AUTOSAR XML (schema 4-3-0)
standard types defined: boolean, float32, sint16, sint32, sint8, uint16, uint32, uint64, uint8
package /Clusters
  ethernet cluster EthernetCluster1: baudrate=100000, protocol-name=ETHERNET
    ethernet physical channel RdrNet: comm-connectors=[cnctr_ADAS_RdrNet, cnctr_RDR_RdrNet, cnctr_External_Tool]
      pdu triggering PDUTriggering1: pdu=GenerelPurposePDU1, from ADAS
      pdu triggering PDUTriggering2: pdu=GenerelPurposePDU2, to ADAS
      pdu triggering PDUTriggering3: pdu=GenerelPurposePDU3, from RDR
      pdu triggering PDUTriggering4: pdu=GenerelPurposePDU4, to RDR
      pdu triggering PDUTriggering7: pdu=GenerelPurposePDU7, to RDR
      pdu triggering PDUTriggering9: pdu=GenerelPurposePDU9, to ADAS
      pdu triggering PDUTriggering12_Vehicle_Status_ADAS_to_RDR1: pdu=signalPdu_ADAS_Vehicle_Status, from ADAS, to RDR
      pdu triggering PDUTriggering14_Detections_RDR1_to_ADAS: pdu=signalPdu_RDR_1_Detections, from RDR, to ADAS
      pdu triggering PDUTriggering15_SW_Info_RDR1_to_ADAS: pdu=signalPdu_RDR_1_SW_Info, from RDR, to ADAS
      pdu triggering PDUTriggering16_RDR_Status_RDR1_to_ADAS: pdu=signalPdu_RDR_1_Status, from RDR, to ADAS
      pdu triggering PDUTriggering14_Detections_RDR1_to_ADAS_Transport: pdu=signalPdu_RDR_1_Detections_Transport, from RDR, to ADAS
      10 x network endpoint:
        NEP_ANY_IP: network-endpoint-addresses=ipv-4-configuration={ipv-4-address=ANY, ipv-4-address-source=FIXED}
        NEP_ADAS_RdrNet_CtrlRxMulticast: network-endpoint-addresses=ipv-4-configuration={ipv-4-address=239.192.255.251, ipv-4-address-source=FIXED}
        NEP_ADAS_RdrNet_Unicast: network-endpoint-addresses=ipv-4-configuration={ipv-4-address=192.168.1.100, ipv-4-address-source=FIXED, network-mask=255.255.255.0}
        NEP_SRR_1_RdrNet_Unicast: network-endpoint-addresses=ipv-4-configuration={ipv-4-address=192.168.1.71, ipv-4-address-source=FIXED, network-mask=255.255.255.0}
        NEP_RdrNet_ExternalTool: network-endpoint-addresses=ipv-4-configuration={ipv-4-address=192.168.1.40, ipv-4-address-source=FIXED, network-mask=255.255.255.0}
        SD_AnyNEP_ADAS_1
        SD_AnyNEP_RDR_1
        SD_AnyNEP_RDR_SRR_2_1
        SD_AnyNEP_RDR_2
        SD_AnyNEP_ADAS_2
      so-ad-config:
        6 x socket connection bundle:
          ConnectionBundle_ADAS: socket-connection{client-port=SocAddr_RDR_1_RdrNet_UDP_30501_client, pdus=socket-connection-ipdu-identifier={header-id=16809985, pdu-triggering=PDUTriggering12_Vehicle_Status_ADAS_to_RDR1, routing-group=SoAdRoutingGroup1}}, server-port=SocAddr_ADAS_RdrNet_UDP_34501_server
          ConnectionBundle_RDR_1: socket-connection{client-port=SocAddr_ADAS_RdrNet_UDP_30501_client, pdus=[{header-id=1081345, pdu-triggering=PDUTriggering14_Detections_RDR1_to_ADAS_Transport, routing-group=SoAdRoutingGroup2}, {header-id=1212418, pdu-triggering=PDUTriggering15_SW_Info_RDR1_to_ADAS, routing-group=SoAdRoutingGroup3}, {header-id=1146883, pdu-triggering=PDUTriggering16_RDR_Status_RDR1_to_ADAS, routing-group=SoAdRoutingGroup4}]}, server-port=SocAddr_RDR_1_RdrNet_UDP_34501_server
          ConnectionBundle1: socket-connection{client-port=SD_SocketAddress_Client1, pdus=[{header-id=4294934784, pdu-triggering=PDUTriggering1}, {header-id=4294934784, pdu-triggering=PDUTriggering2}]}, server-port=SD_SocketAddress_ADAS1
          ConnectionBundle2: socket-connection{client-port=SD_SocketAddress_Client2, pdus=[{header-id=4294934784, pdu-triggering=PDUTriggering3}, {header-id=4294934784, pdu-triggering=PDUTriggering4}]}, server-port=SD_SocketAddress_RDR1
          ConnectionBundle4: socket-connection{client-port=SD_SocketAddress_Client4, pdus=socket-connection-ipdu-identifier={header-id=4294934784, pdu-triggering=PDUTriggering7}}, server-port=SD_SocketAddress_RDR2
          ConnectionBundle6: socket-connection{client-port=SD_SocketAddress_Client6, pdus=socket-connection-ipdu-identifier={header-id=4294934784, pdu-triggering=PDUTriggering9}}, server-port=SD_SocketAddress_ADAS2
        15 x socket address:
          SocAddr_ADAS_RdrNet_UDP_30501_client: connector=cnctr_ADAS_RdrNet
            application endpoint AEP_AEP_ADAS_RdrNet_UDP_30501_UDP30501_client: network-endpoint=NEP_ADAS_RdrNet_Unicast, tp-configuration=udp-tp=udp-tp-port={dynamically-assigned=false, port-number=30501}
              consumed service instance consService_ADAS_Detections_from_RDR_1: provided-service-instance=provService_RDR_1_Detections, sd-client-config={client-service-major-version=1, client-service-minor-version=0, initial-find-behavior={initial-delay-max-value=0.01, initial-delay-min-value=0.01, initial-repetitions-base-delay=0.03, initial-repetitions-max=3}, request-response-delay={max-value=0.01, min-value=0.01}, ttl=3}
                consumed event group consServiceGrp_ADAS_Detections_from_RDR_1: event-group-identifier=0x1, instance-identifier=1, routing-group=SoAdRoutingGroup2, sd-client-config={client-service-major-version=1, client-service-minor-version=0, initial-find-behavior={initial-delay-max-value=0.01, initial-delay-min-value=0.01, initial-repetitions-base-delay=0.03, initial-repetitions-max=3}, request-response-delay={max-value=0.01, min-value=0.01}, ttl=3}
              consumed service instance consService_ADAS_SW_Info_from_RDR_1: provided-service-instance=provService_RDR_1_SW_Info, sd-client-config={client-service-major-version=1, client-service-minor-version=0, initial-find-behavior={initial-delay-max-value=0.01, initial-delay-min-value=0.01, initial-repetitions-base-delay=0.03, initial-repetitions-max=3}, request-response-delay={max-value=0.01, min-value=0.01}, ttl=3}
                consumed event group consServiceGrp_ADAS_SW_Info_from_RDR_1: event-group-identifier=0x1, instance-identifier=1, routing-group=SoAdRoutingGroup3, sd-client-config={client-service-major-version=1, client-service-minor-version=0, initial-find-behavior={initial-delay-max-value=0.01, initial-delay-min-value=0.01, initial-repetitions-base-delay=0.03, initial-repetitions-max=3}, request-response-delay={max-value=0.01, min-value=0.01}, ttl=3}
              consumed service instance consService_ADAS_Status_from_RDR_1: provided-service-instance=provService_RDR_1_Status, sd-client-config={client-service-major-version=1, client-service-minor-version=0, initial-find-behavior={initial-delay-max-value=0.01, initial-delay-min-value=0.01, initial-repetitions-base-delay=0.03, initial-repetitions-max=3}, request-response-delay={max-value=0.01, min-value=0.01}, ttl=3}
                consumed event group consServiceGrp_ADAS_Status_from_RDR_1: event-group-identifier=0x1, instance-identifier=1, routing-group=SoAdRoutingGroup4, sd-client-config={client-service-major-version=1, client-service-minor-version=0, initial-find-behavior={initial-delay-max-value=0.01, initial-delay-min-value=0.01, initial-repetitions-base-delay=0.03, initial-repetitions-max=3}, request-response-delay={max-value=0.01, min-value=0.01}, ttl=3}
          SocAddr_ADAS_RdrNet_UDP_34501_server: connector=cnctr_ADAS_RdrNet
            application endpoint AEP_AEP_ADAS_RdrNet_UDP_34501_UDP34501_server: network-endpoint=NEP_ADAS_RdrNet_Unicast, tp-configuration=udp-tp=udp-tp-port={dynamically-assigned=false, port-number=34501}
              provided service instance provService_ADAS_Vehicle_Status: instance-identifier=1, sd-server-config={initial-offer-behavior={initial-delay-max-value=0.01, initial-delay-min-value=0.01, initial-repetitions-base-delay=0.03, initial-repetitions-max=3}, offer-cyclic-delay=1, request-response-delay={max-value=0.01, min-value=0.01}, server-service-major-version=1, server-service-minor-version=0, ttl=3}, service-identifier=256
                event handler EventGroup_ADAS:
                  consumed-event-group=consServiceGrp_RDR_1_ADAS_Vehicle_Status
                  routing-group=SoAdRoutingGroup1
                  sd-server-config={initial-offer-behavior={initial-delay-max-value=0.01, initial-delay-min-value=0.01, initial-repetitions-base-delay=0.03, initial-repetitions-max=3}, offer-cyclic-delay=1, request-response-delay={max-value=0.01, min-value=0.01}, server-service-major-version=1, server-service-minor-version=0, ttl=3}
          SocAddr_RDR_1_RdrNet_UDP_30501_client: connector=cnctr_RDR_RdrNet
            application endpoint AEP_AEP_RDR_1_RdrNet_UDP_30501_client: network-endpoint=NEP_SRR_1_RdrNet_Unicast, tp-configuration=udp-tp=udp-tp-port={dynamically-assigned=false, port-number=30501}
              consumed service instance consService_RDR_1_ADAS_Vehicle_Status: provided-service-instance=provService_ADAS_Vehicle_Status, sd-client-config={client-service-major-version=1, client-service-minor-version=0, initial-find-behavior={initial-delay-max-value=0.01, initial-delay-min-value=0.01, initial-repetitions-base-delay=0.03, initial-repetitions-max=3}, request-response-delay={max-value=0.01, min-value=0.01}, ttl=3}
                consumed event group consServiceGrp_RDR_1_ADAS_Vehicle_Status: event-group-identifier=0x1, instance-identifier=1, routing-group=SoAdRoutingGroup1, sd-client-config={client-service-major-version=1, client-service-minor-version=0, initial-find-behavior={initial-delay-max-value=0.01, initial-delay-min-value=0.01, initial-repetitions-base-delay=0.03, initial-repetitions-max=3}, request-response-delay={max-value=0.01, min-value=0.01}, ttl=3}
          SocAddr_RDR_1_RdrNet_UDP_34501_server: connector=cnctr_RDR_RdrNet
            application endpoint AEP_AEP_RDR_1_RdrNet_UDP_34501_server: network-endpoint=NEP_SRR_1_RdrNet_Unicast, tp-configuration=udp-tp=udp-tp-port={dynamically-assigned=false, port-number=34501}
              provided service instance provService_RDR_1_Detections: instance-identifier=1, sd-server-config={initial-offer-behavior={initial-delay-max-value=0.01, initial-delay-min-value=0.01, initial-repetitions-base-delay=0.03, initial-repetitions-max=3}, offer-cyclic-delay=1, request-response-delay={max-value=0.01, min-value=0.01}, server-service-major-version=1, server-service-minor-version=0, ttl=3}, service-identifier=16
                event handler EventGroup_RDR_1:
                  consumed-event-group=consServiceGrp_ADAS_Detections_from_RDR_1
                  routing-group=SoAdRoutingGroup2
                  sd-server-config={initial-offer-behavior={initial-delay-max-value=0.01, initial-delay-min-value=0.01, initial-repetitions-base-delay=0.03, initial-repetitions-max=3}, offer-cyclic-delay=1, request-response-delay={max-value=0.01, min-value=0.01}, server-service-major-version=1, server-service-minor-version=0, ttl=3}
              provided service instance provService_RDR_1_SW_Info: instance-identifier=1, sd-server-config={initial-offer-behavior={initial-delay-max-value=0.01, initial-delay-min-value=0.01, initial-repetitions-base-delay=0.03, initial-repetitions-max=3}, offer-cyclic-delay=1, request-response-delay={max-value=0.01, min-value=0.01}, server-service-major-version=1, server-service-minor-version=0, ttl=3}, service-identifier=18
                event handler EventGroup_RDR_1:
                  consumed-event-group=consServiceGrp_ADAS_SW_Info_from_RDR_1
                  routing-group=SoAdRoutingGroup3
                  sd-server-config={initial-offer-behavior={initial-delay-max-value=0.01, initial-delay-min-value=0.01, initial-repetitions-base-delay=0.03, initial-repetitions-max=3}, offer-cyclic-delay=1, request-response-delay={max-value=0.01, min-value=0.01}, server-service-major-version=1, server-service-minor-version=0, ttl=3}
              provided service instance provService_RDR_1_Status: instance-identifier=1, sd-server-config={initial-offer-behavior={initial-delay-max-value=0.01, initial-delay-min-value=0.01, initial-repetitions-base-delay=0.03, initial-repetitions-max=3}, offer-cyclic-delay=1, request-response-delay={max-value=0.01, min-value=0.01}, server-service-major-version=1, server-service-minor-version=0, ttl=3}, service-identifier=17
                event handler EventGroup_RDR_1:
                  consumed-event-group=consServiceGrp_ADAS_Status_from_RDR_1
                  routing-group=SoAdRoutingGroup4
                  sd-server-config={initial-offer-behavior={initial-delay-max-value=0.01, initial-delay-min-value=0.01, initial-repetitions-base-delay=0.03, initial-repetitions-max=3}, offer-cyclic-delay=1, request-response-delay={max-value=0.01, min-value=0.01}, server-service-major-version=1, server-service-minor-version=0, ttl=3}
          SocAddr_External_Tool: connector=cnctr_External_Tool
            application endpoint AEP_AEP_External_Tool: network-endpoint=NEP_RdrNet_ExternalTool, tp-configuration=udp-tp=udp-tp-port={dynamically-assigned=false, port-number=5555}
          SocAddr_Ctrl_ANY: multicast-connector=[cnctr_ADAS_RdrNet, cnctr_RDR_RdrNet]
            application endpoint AEP_SocAddr_Ctrl_ANY: network-endpoint=NEP_ANY_IP
          SocAddr_SD_Multicast: multicast-connector=[cnctr_ADAS_RdrNet, cnctr_RDR_RdrNet]
            application endpoint AEP_SocAddr_SD_Multicast: network-endpoint=NEP_ADAS_RdrNet_CtrlRxMulticast, tp-configuration=udp-tp=udp-tp-port=port-number=30490
          SD_SocketAddress_ADAS1: connector=cnctr_ADAS_RdrNet
            application endpoint SD_SocketAddress_ADAS1: network-endpoint=NEP_ADAS_RdrNet_Unicast, tp-configuration=udp-tp=udp-tp-port={dynamically-assigned=false, port-number=30490}
          SD_SocketAddress_Client1
            application endpoint SD_SocketAddress_Client1: network-endpoint=SD_AnyNEP_ADAS_1, tp-configuration=udp-tp=udp-tp-port=dynamically-assigned=true
          SD_SocketAddress_RDR1: connector=cnctr_RDR_RdrNet
            application endpoint SD_SocketAddress_RDR1: network-endpoint=NEP_SRR_1_RdrNet_Unicast, tp-configuration=udp-tp=udp-tp-port={dynamically-assigned=false, port-number=30490}
          SD_SocketAddress_Client2
            application endpoint SD_SocketAddress_Client2: network-endpoint=SD_AnyNEP_RDR_1, tp-configuration=udp-tp=udp-tp-port=dynamically-assigned=true
          SD_SocketAddress_RDR2: connector=cnctr_RDR_RdrNet
            application endpoint SD_SocketAddress_RDR2: network-endpoint=NEP_ADAS_RdrNet_CtrlRxMulticast, tp-configuration=udp-tp=udp-tp-port={dynamically-assigned=false, port-number=30490}
          SD_SocketAddress_Client4
            application endpoint SD_SocketAddress_Client4: network-endpoint=SD_AnyNEP_RDR_2, tp-configuration=udp-tp=udp-tp-port=dynamically-assigned=true
          SD_SocketAddress_ADAS2: connector=cnctr_ADAS_RdrNet
            application endpoint SD_SocketAddress_ADAS2: network-endpoint=NEP_ADAS_RdrNet_CtrlRxMulticast, tp-configuration=udp-tp=udp-tp-port={dynamically-assigned=false, port-number=30490}
          SD_SocketAddress_Client6
            application endpoint SD_SocketAddress_Client6: network-endpoint=SD_AnyNEP_ADAS_2, tp-configuration=udp-tp=udp-tp-port=dynamically-assigned=true
package /PDUs/PDU_RdrNet
  pdu signalPdu_ADAS_Vehicle_Status: length=79, transmission-mode-true-timing=event-controlled-timing=number-of-repetitions=0, unused-bit-pattern=255
    signal iSignal_ADAS_Vehicle_Status: start 0, 568 bit, opaque, system signal sysSignal_ADAS_Vehicle_Status, data-transformations=SOMEIP_XFORMER_BE, data-type-policy=TRANSFORMING-I-SIGNAL, implementation-data-type=SR_VEHICLE_STATUS_RECORD, someip-transformation-i-signal-props{transformer=SOMEIP_XFORM_TECH_BE, message-type=NOTIFICATION, session-handling-sr=SESSION-HANDLING-ACTIVE}, transfer-property=TRIGGERED, to RDR
  pdu signalPdu_RDR_1_Detections: length=38632, transmission-mode-true-timing=event-controlled-timing=number-of-repetitions=0, unused-bit-pattern=255
    signal iSignal_RDR_1_Detections: start 0, 309056 bit, opaque, system signal sysSignal_RDR_1_Detections, data-transformations=SOMEIP_XFORMER_BE, data-type-policy=TRANSFORMING-I-SIGNAL, implementation-data-type=SR_DETECTIONS_RECORD, someip-transformation-i-signal-props{transformer=SOMEIP_XFORM_TECH_BE, message-type=NOTIFICATION, session-handling-sr=SESSION-HANDLING-ACTIVE}, transfer-property=TRIGGERED, to ADAS
  general purpose i pdu signalPdu_RDR_1_Detections_Transport: category=SOMEIP_SEGMENTED_IPDU, length=1404
  pdu signalPdu_RDR_1_SW_Info: length=90, transmission-mode-true-timing=event-controlled-timing=number-of-repetitions=0, unused-bit-pattern=255
    signal iSignal_RDR_1_SW_Info: start 0, 656 bit, opaque, system signal sysSignal_RDR_1_SW_Info, data-transformations=SOMEIP_XFORMER_BE, data-type-policy=TRANSFORMING-I-SIGNAL, implementation-data-type=SR_RADAR_SW_INFO_RECORD, someip-transformation-i-signal-props{transformer=SOMEIP_XFORM_TECH_BE, message-type=NOTIFICATION, session-handling-sr=SESSION-HANDLING-ACTIVE}, transfer-property=TRIGGERED, to ADAS
  pdu signalPdu_RDR_1_Status: length=269, transmission-mode-true-timing=event-controlled-timing=number-of-repetitions=0, unused-bit-pattern=255
    signal iSignal_RDR_1_Status: start 0, 2088 bit, opaque, system signal sysSignal_RDR_1_Status, data-transformations=SOMEIP_XFORMER_BE, data-type-policy=TRANSFORMING-I-SIGNAL, implementation-data-type=SR_RADAR_STATUS_RECORD, someip-transformation-i-signal-props{transformer=SOMEIP_XFORM_TECH_BE, message-type=NOTIFICATION, session-handling-sr=SESSION-HANDLING-ACTIVE}, transfer-property=TRIGGERED, to ADAS
package /PDUs/GeneralPurposePDUs
  general purpose pdu GenerelPurposePDU{1..9}: category=SD, length=0
package /Transformer
  data transformation set SOMEIP_XFORMER
    data transformation SOMEIP_XFORMER_BE: execute-despite-data-unavailability=false, transformer-chain=SOMEIP_XFORM_TECH_BE
    data transformation SOMEIP_XFORMER_LE: execute-despite-data-unavailability=false, transformer-chain=SOMEIP_XFORM_TECH_LE
    transformation technology SOMEIP_XFORM_TECH_BE: buffer-properties={buffer-computation=compu-rational-coeffs={compu-numerator=[8, 1], compu-denominator=1}, header-length=64, in-place=false}, protocol=SOMEIP, someip-transformation-description{alignment=8, byte-order=big-endian, interface-version=1}, transformer-class=SERIALIZER, version=1
    transformation technology SOMEIP_XFORM_TECH_LE: buffer-properties={buffer-computation=compu-rational-coeffs={compu-numerator=[8, 1], compu-denominator=1}, header-length=64, in-place=false}, protocol=SOMEIP, someip-transformation-description{alignment=8, byte-order=little-endian, interface-version=1}, transformer-class=SERIALIZER, version=1
package /System
  system System
    system mapping Mapping
      data-mappings:
        data-element=SWC_ADAS_Com.RootComposition.PP_Vehicle_Status.Vehicle_Status, system-signal=sysSignal_ADAS_Vehicle_Status
        data-element=SWC_RDR_1_Veh_Com.RootComposition.PP_DetectionList_Event.DetectionList_Event, system-signal=sysSignal_RDR_1_Detections
        data-element=SWC_ADAS_Com.RootComposition.RP_ADAS_RDR_1_DetectionList.DetectionList_Event, system-signal=sysSignal_RDR_1_Detections
        data-element=SWC_RDR_1_Veh_Com.RootComposition.PP_RDR_Radar_SW_Info.RDR_SW_Info, system-signal=sysSignal_RDR_1_SW_Info
        data-element=SWC_ADAS_Com.RootComposition.RP_ADAS_RDR_1_Radar_SW_Info.RDR_SW_Info, system-signal=sysSignal_RDR_1_SW_Info
        data-element=SWC_RDR_1_Veh_Com.RootComposition.PP_RDR_Radar_Status.RDR_Status, system-signal=sysSignal_RDR_1_Status
        data-element=SWC_ADAS_Com.RootComposition.RP_ADAS_RDR_1_Radar_Status.RDR_Status, system-signal=sysSignal_RDR_1_Status
        data-element=SWC_RDR_1_Veh_Com.RootComposition.RP_Vehicle_Status.Vehicle_Status, system-signal=sysSignal_ADAS_Vehicle_Status
      sw-mappings:
        swc to ecu mapping ECUMapping1: component=RootComposition.SWC_ADAS_Com, ecu-instance=ADAS
        swc to ecu mapping ECUMapping2: component=RootComposition.SWC_RDR_1_Veh_Com, ecu-instance=RDR
    root-software-compositions:
      root sw composition prototype RootComposition: software-composition=ECU_Composition
package /ECUs
  ecu instance ADAS
    ethernet communication controller ADAS_Eth_Controller_1: mac-unicast-address=00:1A:A0:22:0E:A9
      coupling port ADAS_CouplingPort1: connection-negotiation-behavior=MASTER
    ethernet communication connector cnctr_ADAS_RdrNet: comm-controller=ADAS_Eth_Controller_1, pnc-gateway-type=NONE, maximum-transmission-unit=1500
  ecu instance External_Tool
    ethernet communication controller External_Tool_EthConnector1_Controller: mac-unicast-address=00:1B:B0:22:0C:A0
      coupling port Ext_Tool_CouplingPort1: connection-negotiation-behavior=SLAVE
    ethernet communication controller cnctr_External_Tool_Controller: mac-unicast-address=00:1B:B0:22:0C:A0
      coupling port Ext_Tool_CouplingPort1: connection-negotiation-behavior=SLAVE
    ethernet communication connector External_Tool_EthConnector1: comm-controller=External_Tool_EthConnector1_Controller, pnc-gateway-type=NONE
    ethernet communication connector cnctr_External_Tool: comm-controller=cnctr_External_Tool_Controller, pnc-gateway-type=NONE
  ecu instance RDR
    ethernet communication controller RDR_1_Eth_Controller_1: mac-unicast-address=00:1A:A0:22:0E:B0
      coupling port RDR_CouplingPort1: connection-negotiation-behavior=SLAVE
    ethernet communication connector cnctr_RDR_RdrNet: comm-controller=RDR_1_Eth_Controller_1, pnc-gateway-type=NONE, maximum-transmission-unit=1500
package /Interfaces/Events
  4 x sender receiver interface:
    Interface_DetectionList_Event
      data DetectionList_Event: type=SR_DETECTIONS_RECORD
    Interface_RDR_SW_Info_Event
      data RDR_SW_Info: type=SR_RADAR_SW_INFO_RECORD
    Interface_RDR_Status_Event
      data RDR_Status: type=SR_RADAR_STATUS_RECORD
    Interface_Vechicle_Status_Event
      data Vehicle_Status: type=SR_VEHICLE_STATUS_RECORD
package /SoftwareComponents/ApplicationSWComponents
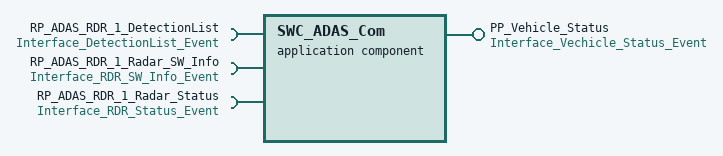
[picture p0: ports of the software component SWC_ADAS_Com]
  application sw component type SWC_ADAS_Com
    provide port PP_Vehicle_Status: provided-interface=Interface_Vechicle_Status_Event
    require port RP_ADAS_RDR_1_DetectionList: required-interface=Interface_DetectionList_Event
    require port RP_ADAS_RDR_1_Radar_SW_Info: required-interface=Interface_RDR_SW_Info_Event
    require port RP_ADAS_RDR_1_Radar_Status: required-interface=Interface_RDR_Status_Event
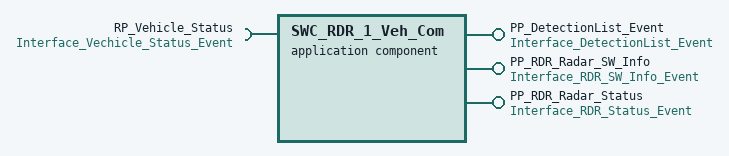
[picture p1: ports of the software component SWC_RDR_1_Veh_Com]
  application sw component type SWC_RDR_1_Veh_Com
    provide port PP_DetectionList_Event: provided-interface=Interface_DetectionList_Event
    provide port PP_RDR_Radar_SW_Info: provided-interface=Interface_RDR_SW_Info_Event
    provide port PP_RDR_Radar_Status: provided-interface=Interface_RDR_Status_Event
    require port RP_Vehicle_Status: required-interface=Interface_Vechicle_Status_Event
package /SoftwareComponents/CompositionSWComponents
  composition sw component type ECU_Composition
    component SWC_ADAS_Com: type=SWC_ADAS_Com
    component SWC_RDR_1_Veh_Com: type=SWC_RDR_1_Veh_Com
    connect SWC_ADAS_Com.PP_Vehicle_Status -> SWC_RDR_1_Veh_Com.RP_Vehicle_Status
    connect SWC_RDR_1_Veh_Com.PP_DetectionList_Event -> SWC_ADAS_Com.RP_ADAS_RDR_1_DetectionList
    connect SWC_RDR_1_Veh_Com.PP_RDR_Radar_SW_Info -> SWC_ADAS_Com.RP_ADAS_RDR_1_Radar_SW_Info
    connect SWC_RDR_1_Veh_Com.PP_RDR_Radar_Status -> SWC_ADAS_Com.RP_ADAS_RDR_1_Radar_Status
package /SoAdRoutingGroups
  5 x so ad routing group, all with event-group-control-type=ACTIVATION-UNICAST:
    SoAdRoutingGroup{1..5}
package /SomeIpTpConfig
  someip tp config SOMEIP_TP_CONFIG: communication-cluster=EthernetCluster1, someip-tp-connection{separation-time=0.001, tp-sdu=PDUTriggering14_Detections_RDR1_to_ADAS, transport-pdu=PDUTriggering14_Detections_RDR1_to_ADAS_Transport}
package /DataTypes
  38 x impl type:
    SR_Alignment_Auto: category=STRUCTURE
      17 x element, all with category=VALUE:
        STS_AAAzimuthStd: base-type=uint8, range phys 0..180, raw 0..180
        STS_AACurrentAzimuth: base-type=sint32, range phys -3.14159..3.14159, raw -314159..314159
        STS_AACurrentElevation: base-type=sint16, range phys -0.1745..0.1745, raw -1745..1745
        STS_AAElevationStd: base-type=uint8, range phys 0..180, raw 0..180
        STS_AlignmentAutoStatus: base-type=uint8, compu {0=Cx0_Off, 1=Cx1_Active, 2=Cx2_Paused, 3=Cx3_Failed; unit NA}, range raw 0..3
        STS_AutoAlignmentFailRootCause: base-type=uint8, compu {0=Cx0_DataQualifierInvalid, 1=Cx1_None, 2=Cx2_SensorFacingDownwards, 3=Cx3_SensorFacingRight, 4=Cx4_SensorFacingLeft, 5=Cx5_InvalidVehicleSignal, 6=Cx6_Blockage, 7=Cx7_OperationModeFaulty; unit NA}, range raw 0..7
        STS_AzimuthErrorNegative: base-type=sint16, range phys -3.14..0, raw -314..0
        STS_AzimuthErrorPositive: base-type=uint16, range phys 0..3.14, raw 0..314
        STS_AzimuthUpdates: base-type=uint32, range phys 0..4294967295, raw 0..4294967295
        STS_ElevationErrorNegative: base-type=sint8, range phys -0.44..0, raw -44..0
        STS_ElevationErrorPositive: base-type=uint8, range phys 0..0.44, raw 0..44
        STS_ElevationUpdates: base-type=uint32, range phys 0..4294967295, raw 0..4294967295
        STS_HostSpdCompensationFactorQF: base-type=uint8, compu {0=Cx0_DRA_QF_INIT, 1=Cx1_DRA_QF_REDUCED, 2=Cx2_DRA_QF_OK; unit NA}, range raw 0..2
        STS_HostSpeedCompensationFactor: base-type=uint8, range phys 0.95..1.05, raw 95..105
        STS_RollErrorPositive: base-type=sint16, range phys -3.14..3.14, raw -314..314
        STS_StartAzimuth: base-type=sint16, range phys -180..180, raw -180..180
        STS_StartElevation: base-type=sint16, range phys -180..180, raw -180..180
    SR_Alignment_Handler: category=STRUCTURE
      18 x element, all with category=VALUE:
        STS_AlignmentAzimuth: base-type=float32, range raw -3.14..3.14
        STS_AlignmentElevation: base-type=float32, range phys -0.1745..0.1745, raw -0.1745..0.1745
        STS_AlignmentError:
          base-type=uint8
          compu {0=Cx0_MaxDurationCrossed, 1=Cx1_OperationModeFaulty_Dyn (OperationModeFaulty _Dyn), 2=Cx2_DataQualifierInvalid_Dyn, 3=Cx3_SensorFacingRight, 4=Cx4_SensorFacingLeft, 5=Cx5_TargetSignalTooWeak, 6=Cx6_TargetSignalTooStrong, 7=Cx7_TargetNotStatic, 8=Cx8_TargetDistanceTooHigh, 9=Cx9_TargetDistanceTooLow, 10=CxA_TargetNotFound, 11=CxB_Interference, 12=CxC_InvalidInput, 13=CxD_InvalidVehicleSignal, 14=CxE_Blockage, 15=CxF_MaxDistanceCrossed; unit NA}
          range raw 0..15
        STS_AlignmentModeIn: base-type=uint8, compu {0=Cx0_Off, 1=Cx1_AutoAlignment, 2=Cx2_ShortTrackAlignment, 3=Cx3_ServiceAlignment, 4=Cx4_StaticAlignment, 5=Cx5_ManualAlignment; unit NA}, range raw 0..5
        STS_AlignmentModeOut: base-type=uint8, compu {0=Cx0_Off, 1=Cx1_AutoAlignment, 2=Cx2_ShortTrackAlignment, 3=Cx3_ServiceAlignment, 4=Cx4_StaticAlignment; unit NA}, range raw 0..4
        STS_AzimuthStd: base-type=float32, range raw 0..3.14
        STS_CalDisplay: base-type=boolean, compu {0=Cx0_None, 1=Cx1_Display; unit NA}, range raw 0..1
        STS_CalTime: base-type=float32, range phys 0..3600, raw 0..3600
        STS_CoordinateSystemInput: base-type=uint8, compu {0=Cx0_DRA_DET_COORD_SYS_UNDEFINED, 1=Cx1_DRA_DET_COORD_SYS_SAE, 2=Cx2_DRA_DET_COORD_SYS_ISO; unit NA}, range raw 0..2
        STS_ElevationStd: base-type=float32, range raw 0..3.14
        STS_InitAlignmentResultAzimuth: base-type=float32, range phys -6..6, raw -6..6
        STS_InitAlignmentResultElevation: base-type=float32, range phys -6..6, raw -6..6
        STS_InitAlignResultAzimuthUpdate: base-type=uint32, range phys 0..4294967295, raw 0..4294967295
        STS_InitAlignRsltElevationUpdate: base-type=uint32, range phys 0..4294967295, raw 0..4294967295
        STS_InitAlignRsltHostSpdCompFac: base-type=float32, range raw 0.95..1.05
        STS_InitLastSuccessfulAlignMode: base-type=uint8, compu {0=Cx0_None, 1=Cx1_NotUsed, 2=Cx2_ShortTrackAlignment, 3=Cx3_ServiceAlignment, 4=Cx4_StaticAlignment, 5=Cx5_ExternalAlignment; unit NA}, range raw 0..5
        STS_ProgressPercent: base-type=float32, range phys 0..100, raw 0..100
        STS_RadarTypeInput: base-type=uint8, compu {0=Cx0_DRA_RADAR_TYPE_UNKNOWN, 1=Cx1_DRA_RADAR_TYPE_SRR6, 2=Cx2_DRA_RADAR_TYPE_SRR6P_HIGH_GAIN, 3=Cx3_DRA_RADAR_TYPE_SRR6P_LOW_GAIN, 4=Cx4_DRA_RADAR_TYPE_SRR7P, 5=Cx5_DRA_RADAR_TYPE_FLR4_, 6=Cx6_DRA_RADAR_TYPE_FLR4P, 7=Cx7_DRA_RADAR_TYPE_FLR7; unit NA}, range raw 0..7
    SR_Alignment_Service: category=STRUCTURE
      8 x element, all with category=VALUE:
        STS_AlignmentServiceStatus: base-type=uint8, compu {0=Cx0_Off, 1=Cx1_Running, 2=Cx2_Paused, 3=Cx3_Failed, 4=Cx4_Success; unit NA}, range raw 0..4
        STS_AverageNumberOfDetections: base-type=float32, range raw 0..655.35
        STS_AverageSpeed: base-type=sint16, range phys -32768..32767, raw -32768..32767
        STS_DistanceAbsolute: base-type=uint32, range phys 0..4294967295, raw 0..4294967295
        STS_DistanceEffective: base-type=uint32, range phys 0..4294967295, raw 0..4294967295
        STS_DurationAbsolute: base-type=uint32, range phys 0..4294967295, raw 0..4294967295
        STS_DurationEffective: base-type=uint32, range phys 0..4294967295, raw 0..4294967295
        STS_VehicleCondition: base-type=uint8, compu {0=Cx0_VelocityTooLow, 1=Cx1_VelocityTooHigh, 2=Cx2_YawRateTooHigh, 3=Cx3_QualityFctrVelocityInsufficient, 4=Cx4_QualityFctrYawRateInsufficient, 5=Cx5_VehicleInReverse, 6=Cx6_NoIssue; unit NA}, range raw 0..6
    SR_Alignment_Short_Track: category=STRUCTURE
      element STS_AlignmentShortTrackStatus: category=VALUE, base-type=uint8, compu {0=Cx0_Off, 1=Cx1_Running, 2=Cx2_Paused, 3=Cx3_Failed, 4=Cx4_Success; unit NA}, range raw 0..4
    SR_Alignment_Static: category=STRUCTURE
      8 x element, all with category=VALUE:
        STS_AlignmentStaticStatus: base-type=uint8, compu {0=Cx0_Off, 1=Cx1_Running, 2=Cx2_Paused, 3=Cx3_Failed, 4=Cx4_Success}, range raw 0..4
        STS_ImpactByInterference: base-type=boolean, range phys 0..1, raw 0..1
        STS_Measured_Range: base-type=float32, range phys 940..5410, raw 940..5410
        STS_MeasuredRangeRate: base-type=float32, range raw -0.02..0.02
        STS_MeasuredRangeRateStd: base-type=float32, range raw 0..32.767
        STS_MeasuredRangeStd: base-type=float32, range phys 0..65535, raw 0..65535
        STS_MeasuredRCS: base-type=float32, range phys -5..40, raw -5..40
        STS_MeasuredRCSStd: base-type=float32, range raw 0..327.67
    SR_Capability_Damping: category=STRUCTURE
      4 x element, all with category=VALUE:
        CAP_DampingActive: base-type=boolean, compu {0=Cx0_Off, 1=Cx1_Active; unit NA}, range raw 0..1
        CAP_DampingCurrent: base-type=uint16, range phys 0..255, raw 0..25500
        CAP_DampingStandardDeviation: base-type=uint8, range phys 0..255, raw 0..255
        CAP_DampingStatus: base-type=uint8, compu {0=Cx0_Faulty, 1=Cx1_Ok, 2=Cx2_Reserved, 3=Cx3_Initialization, 4=Cx4_Invalid; unit NA}, range raw 0..4
    SR_Capability_Radar_Performance: category=STRUCTURE
      9 x element, all with category=VALUE:
        CAP_BlockageActive: base-type=boolean, compu {0=Cx0_Active, 1=Cx1_Off; unit NA}, range raw 0..1
        CAP_BlockageProbability: base-type=uint8, range phys 0..100, raw 0..100
        CAP_BlockageSensitivity: base-type=uint8, compu {0=Cx0_Low, 1=Cx1_Mid, 2=Cx2_High, 3=Cx3_Invalid; unit NA}, range raw 0..3
        CAP_BlockageStatus: base-type=uint8, compu {0=Cx0_Faulty, 1=Cx1_Ok, 2=Cx2_Reserved, 3=Cx3_Initialization, 4=Cx4_Invalid; unit NA}, range raw 0..4
        CAP_BlockageValue: base-type=uint8, compu {0=Cx0_Not_Blocked, 1=Cx1_Slightly_Blocked, 2=Cx2_Moderately_Blocked, 3=Cx3_Highly_Blocked, 4=Cx4_Fully_Blocked, 5=Cx5_Limited_Sight, 6=Cx6_Invalid; unit NA}, range raw 0..6
        CAP_FreeSightCheckActive: base-type=uint8, compu {0=Cx0_Active, 1=Cx1_Inactive, 2=Cx2_Paused, 3=Cx3_Invalid; unit NA}, range raw 0..3
        CAP_FreeSightCheckStatus: base-type=uint8, compu {0=Cx0_Ok, 1=Cx1_Failed, 2=Cx2_Invalid; unit NA}, range raw 0..2
        CAP_SLBlockageFilterValue: base-type=uint8, range phys 0..35, raw 0..35
        CAP_SLBlockageFlag: base-type=boolean, compu {0=Cx0_Not_Degraded, 1=Cx1_Degraded; unit NA}, range raw 0..1
    SR_Capability_Range_Detection: category=STRUCTURE
      7 x element:
        CAP_AngleAzimuthRangeEnd: category=VALUE, base-type=sint16, range phys -180..180, raw -180..180
        CAP_AngleAzimuthRangeStart: category=VALUE, base-type=sint16, range phys -180..180, raw -180..180
        CAP_MaxDetectionRangeCar: category=ARRAY
          element Element: array-size=3, array-size-semantics=FIXED-SIZE, implementation-data-type=SR_Detection_RangeArray
        CAP_MaxDetRangeMotorbike: category=ARRAY
          element Element: array-size=3, array-size-semantics=FIXED-SIZE, implementation-data-type=SR_Detection_RangeArray
        CAP_MaxDetRangePedestrian: category=ARRAY
          element Element: array-size=3, array-size-semantics=FIXED-SIZE, implementation-data-type=SR_Detection_RangeArray
        CAP_RangeEstimationActive: category=VALUE, base-type=boolean, compu {0=Cx0_Off, 1=Cx1_Active; unit NA}, range raw 0..1
        CAP_RangeEstimationStatus: category=VALUE, base-type=uint8, compu {0=Cx0_Faulty, 1=Cx1_Ok, 2=Cx2_Reserved, 3=Cx3_Initialization, 4=Cx4_Invalid; unit NA}, range raw 0..4
    SR_Capability_SLL_Monitoring: category=STRUCTURE
      element CAP_SideLobeLevelBeamformer: category=VALUE, base-type=uint8, range phys 0..255, raw 0..255
      element CAP_SLLMonitoringActive: category=VALUE, base-type=boolean, compu {0=Cx0_Off, 1=Cx1_Active; unit NA}, range raw 0..1
      element CAP_SLLMonitoringStatus: category=VALUE, base-type=uint8, compu {0=Cx0_Faulty, 1=Cx1_Ok, 2=Cx2_Reserved, 3=Cx3_Initialization, 4=Cx4_Invalid; unit NA}, range raw 0..4
    SR_DATA_ID: category=VALUE, base-type=uint32
    SR_Det_Header_Record: category=STRUCTURE
      7 x element, all with category=TYPE_REFERENCE:
        HED_SENSOR_COVERAGE: implementation-data-type=SR_Header_SensorCoverage
        HED_RADAR_STATE: implementation-data-type=SR_Header_RadarState
        HED_ALIGNMENT: implementation-data-type=SR_Header_Alignment
        HED_TIMING_PROFILES: implementation-data-type=SR_Header_Cores_TimingMeasure
        HED_TIMESTAMP: implementation-data-type=SR_Header_TimeStamp
        HED_DETECTION_INFO: implementation-data-type=SR_Header_InfoDetection
        HED_INTERFACE_VERSION: implementation-data-type=SR_Header_Interface_Version
    SR_Detection_RangeArray: category=VALUE, base-type=float32, range phys 0..500, raw 0..32000
    SR_Detection_Record: category=STRUCTURE
      19 x element, all with category=VALUE:
        DET_AZIMUTH: base-type=float32, compu {identical; unit rad}, range raw -3.4e+38..3.4e+38
        DET_AZIMUTH_ERR: base-type=float32, compu {identical; unit rad}, range raw -3.4e+38..3.4e+38
        DET_BI_STATIC_FLAG: base-type=boolean, range phys 0..1, raw 0..1
        DET_CONFD_AZIMUTH: base-type=uint8, compu {0=Cx0_High (High), 1=Cx1_MidHigh (MidHigh), 2=Cx2_MidLow (MidLow), 3=Cx3_Low (Low)}, range raw 0..3
        DET_CONFD_ELEVATION: base-type=uint8, compu {0=Cx0_High (High), 1=Cx1_MidHigh (MidHigh), 2=Cx2_MidLow (MidLow), 3=Cx3_Low (Low)}, range raw 0..3
        DET_ELEVATION: base-type=float32, compu {identical; unit rad}, range raw -3.4e+38..3.4e+38
        DET_ELEVATION_ERR: base-type=float32, compu {identical; unit rad}, range raw -3.4e+38..3.4e+38
        DET_EXISTENCE_PROB: base-type=float32, compu {identical; unit ratio}, range raw 0..1
        DET_HVC_FLAG: base-type=boolean, range phys 0..1, raw 0..1
        DET_OUTSIDE_SECTOR: base-type=boolean, range phys 0..1, raw 0..1
        DET_POINT_TARGET_PROB: base-type=float32, compu {identical; unit ratio}, range raw 0..1
        DET_RANGE: base-type=float32, compu {identical; unit m}, range raw 0..500
        DET_RANGE_ERR: base-type=float32, compu {identical; unit m}, range raw -3.4e+38..3.4e+38
        DET_RANGE_VELOCITY: base-type=float32, compu {identical; unit m/s}, range raw -3.4e+38..3.4e+38
        DET_RANGE_VELOCITY_ERR: base-type=float32, compu {identical; unit m/s}, range raw -3.4e+38..3.4e+38
        DET_RCS: base-type=float32, compu {identical; unit dBsm}, range raw -3.4e+38..3.4e+38
        DET_SNR: base-type=float32, compu {identical; unit dB}, range raw -3.4e+38..3.4e+38
        DET_SUPER_RES_TARGET: base-type=uint8, range phys 0..1, raw 0..1
        DET_VALID_FLAG: base-type=boolean, range phys 0..1, raw 0..1
    SR_DETECTIONS_RECORD: category=STRUCTURE
      element DET_HEADER_STRUCT: implementation-data-type=SR_Det_Header_Record
      element DET_EtoE_HDR: implementation-data-type=SR_EtoE_HDR
      element DETECTIONS_ARRAY: category=ARRAY
        element Dimension: array-size=400, array-size-semantics=FIXED-SIZE, implementation-data-type=SR_Detection_Record
    SR_EtoE_HDR: category=STRUCTURE
      4 x element, all with category=VALUE:
        EtoE_CRC: base-type=uint64
        EtoE_COUNTER: base-type=uint32
        EtoE_DATA_ID: base-type=uint32
        EtoE_LENGTH: base-type=uint32
    SR_Header_Alignment: category=STRUCTURE
      4 x element, all with category=VALUE:
        HED_ALIGN_HOR_QF: base-type=uint8, compu {0=Cx0_Undefined (Undefined), 1=Cx1_Temporarily_undefined_Faulty_ (Temporarily_Undefined_Faulty) (Temporarily undefined (Faulty)), 2=Cx2_Innacurate (Innacurate), 3=Cx3_Accurate (Accurate)}, range raw 0..3
        HED_ALIGN_HOR_REF: base-type=float32, compu {identical; unit rad}, range raw -3.4e+38..3.4e+38
        HED_ALIGN_VER_QF: base-type=uint8, compu {0=Cx0_Undefined (Undefined), 1=Cx1_Temporarily_undefined_Faulty_ (Temporarily_Undefined_Faulty) (Temporarily undefined (Faulty)), 2=Cx2_Innacurate (Innacurate), 3=Cx3_Accurate (Accurate)}, range raw 0..3
        HED_ALIGN_VER_REF: base-type=float32, compu {identical; unit rad}, range raw -3.4e+38..3.4e+38
    SR_Header_Cores_TimingMeasure: category=STRUCTURE
      8 x element, all with category=VALUE, base-type=float32, range raw -3.4e+38..3.4e+38:
        HED_AF_TIME_INST
        HED_AF_TIME_PEAK
        HED_MAIN_CORE_TIME_INST
        HED_MAIN_CORE_TIME_PEAK
        HED_RDD_CORE_TIME_INST
        HED_RDD_CORE_TIME_PEAK
        HED_SP_CORE_TIME_INST
        HED_SP_CORE_TIME_PEAK
    SR_Header_InfoDetection: category=STRUCTURE
      8 x element, all with category=VALUE:
        HED_DET_BI_STATIC_COUNT: base-type=uint8, range phys 0..255, raw 0..255
        HED_DET_NUM_OF_1PASS: base-type=uint16, range phys 0..1023, raw 0..1023
        HED_DET_NUM_OF_2PASS: base-type=uint16, range phys 0..511, raw 0..511
        HED_MAX_NUM_OF_DETECTIONS: base-type=uint16, range phys 0..400, raw 0..400
        HED_NUM_OF_RESTBINS_USED: base-type=uint16, range phys 0..511, raw 0..511
        HED_OPERATION_MODE: base-type=uint8, compu {0=Cx0_Init_MCU (Init_MCU), 1=Cx1_Radar_Not_Configured (Radar_Not_Configured), 2=Cx2_Operational (Operational), 3=Cx3_Faulty (Faulty), 4=Cx4_Shutdown_Initiated (Shutdown_Initiated), 5=Cx5_Power_Off (Power_Odd)}, range raw 0..5
        HED_PROCESSED_RANGE: base-type=uint16, range phys 0..500, raw 0..500
        HED_SLOPE_CORR_EXECUTIONFLAG: base-type=uint8, compu {0=Cx0_AzimuthElevationNotCompensated (AzimuthElevationNotCompensated), 1=Cx1_AzimuthCompensated (AzimuthCompensated), 2=Cx2_ElevationCompensated (ElevationCompensated), 3=Cx3_AzimuthElevationCompensated (AzimuthElevationCompensated)}, range raw 0..3
    SR_Header_Interface_Version: category=STRUCTURE
      element HED_INTRFC_VERSION_ID_MAJOR: category=VALUE, base-type=uint8, range phys 0..255, raw 0..255
      element HED_INTRFC_VERSION_ID_MINOR: category=VALUE, base-type=uint8, range phys 0..255, raw 0..255
      element HED_INTRFC_VERSION_ID_PATCH: category=VALUE, base-type=uint8, range phys 0..255, raw 0..255
    SR_Header_RadarState: category=STRUCTURE
      5 x element, all with category=VALUE:
        HED_DATA_QUALIFIER: base-type=uint8, compu {0=Cx0_Invalid (Invalid), 1=Cx1_Not_Available (Not_Available), 2=Cx2_Reduced_In_Performance (Reduced_In_Performance), 3=Cx3_Test_Mode (Test_Mode), 4=Cx4_Normal (Normal), 5=Cx5_Reduced_In_Coverage (Reduced_In_Coverage), 6=Cx6_Reduced_In_Perf_And_Cov (Reduced_In_Perf_And_Cov), 7=Cx7_Unknown (Unknown)}, range raw 0..7
        HED_LOOK_ID: base-type=uint8, compu {0=Cx0_LOOK_A (LOOK_A), 1=Cx1_LOOK_B (LOOK_B), 2=Cx2_LOOK_C (LOOK_C), 3=Cx3_LOOK_D (LOOK_D)}, range raw 0..7
        HED_LOOK_INDEX: base-type=uint16, range phys 0..65535, raw 0..65535
        HED_NUM_OF_VALID_DETECTIONS: base-type=uint16, range phys 0..500, raw 0..500
        HED_SCAN_INDEX: base-type=uint16, range phys 0..65535, raw 0..65535
    SR_Header_SensorCoverage: category=STRUCTURE
      8 x element, all with category=VALUE, base-type=float32:
        HED_DET_RANGE_MAX: compu {identical; unit m}, range raw 0..500
        HED_DET_RANGE_MIN: compu {identical; unit m}, range raw 0..500
        HED_DET_SPEED_RANGE_MAX: compu {identical; unit m/s}, range raw -3.4e+38..3.4e+38
        HED_DET_SPEED_RANGE_MIN: compu {identical; unit m/s}, range raw -3.4e+38..3.4e+38
        HED_FOV_HOR_MAX: compu {identical; unit rad}, range raw -3.4e+38..3.4e+38
        HED_FOV_HOR_MIN: compu {identical; unit rad}, range raw -3.4e+38..3.4e+38
        HED_FOV_VER_MAX: compu {identical; unit rad}, range raw -3.4e+38..3.4e+38
        HED_FOV_VER_MIN: compu {identical; unit rad}, range raw -3.4e+38..3.4e+38
    SR_Header_TimeStamp: category=STRUCTURE
      5 x element, all with category=VALUE:
        HED_SENSOR_TIME_STAMP_NS: base-type=uint32, range phys 0..4294967295, raw 0..4294967295
        HED_SENSOR_TIME_STAMP_SEC: base-type=uint32, range phys 0..4294967295, raw 0..4294967295
        HED_TIME_SYNC_SRC_MASTER: base-type=boolean, compu {0=Cx0_LOCAL, 1=Cx1_GLOBAL}, range raw 0..1
        HED_TIME_SYNC_VALIDITY_FLAG: base-type=boolean, range phys 0..1, raw 0..1
        HED_TRIGGER_TIME: base-type=uint32, range phys 0..4294967295, raw 0..4294967295
    SR_RADAR_STATUS_RECORD: category=STRUCTURE
      16 x element, all with category=TYPE_REFERENCE:
        STS_ALIGNMENT_HANDLER: implementation-data-type=SR_Alignment_Handler
        STS_ALIGNMENT_AUTO: implementation-data-type=SR_Alignment_Auto
        STS_ALIGNMENT_STATIC: implementation-data-type=SR_Alignment_Static
        STS_ALIGNMENT_SERVICE: implementation-data-type=SR_Alignment_Service
        STS_ALIGN_SHORT_TRACK: implementation-data-type=SR_Alignment_Short_Track
        STS_CAPAB_RDR_PERF: implementation-data-type=SR_Capability_Radar_Performance
        STS_CAPAB_DAMPING: implementation-data-type=SR_Capability_Damping
        STS_CAPAB_RANGE_DET: implementation-data-type=SR_Capability_Range_Detection
        STS_CAPAB_SLL_MONITOR: implementation-data-type=SR_Capability_SLL_Monitoring
        STS_TIMESYNC_STATUS: implementation-data-type=SR_Status_TimeSyncStatus
        STS_SENSOR_PERF: implementation-data-type=SR_Status_SensorPerformance
        STS_TEMPERATURE: implementation-data-type=SR_Status_Temperature
        STS_FAULTS: implementation-data-type=SR_Status_Faults
        STS_RADAR_PROFILE: implementation-data-type=SR_Status_Radar
        STS_VEHICLE: implementation-data-type=SR_Status_Vehicle
        STS_EtoE_HDR: implementation-data-type=SR_EtoE_HDR
    SR_RADAR_SW_INFO_RECORD: category=STRUCTURE
      5 x element, all with category=TYPE_REFERENCE:
        INFO_CALIBRATION_VERSION: implementation-data-type=SR_Status_CalibrationVersion
        INFO_MOUNTING_POS: implementation-data-type=SR_Status_MountingPos
        INFO_SW_VERSION: implementation-data-type=SR_Status_SwVersion
        INFO_HW_CAN_VERSION: implementation-data-type=SR_Status_HW_CAN_Version
        INFO_EtoE_HDR: implementation-data-type=SR_EtoE_HDR
    SR_SystemStatus_AbsoluteTime_impdt: category=STRUCTURE
      6 x element, all with category=VALUE, base-type=uint8:
        SSTS_VEH_AbsoluteTime_Day: range phys 1..31, raw 1..31
        SSTS_VEH_AbsoluteTime_Hour: range phys 0..23, raw 0..23
        SSTS_VEH_AbsoluteTime_Minute: range phys 0..59, raw 0..59
        SSTS_VEH_AbsoluteTime_Month: range phys 0..12, raw 0..12
        SSTS_VEH_AbsoluteTime_Second: range phys 0..59, raw 0..59
        SSTS_VEH_AbsoluteTime_Year: range phys 1970..2100, raw 0..130
    SR_Status_CalibrationVersion: category=STRUCTURE
      7 x element, all with category=VALUE:
        STS_SMC_CAL_VER_MAJOR: base-type=uint16, range phys 0..65535, raw 0..65535
        STS_SMC_CAL_VER_MINOR: base-type=uint16, range phys 0..65535, raw 0..65535
        STS_SMC_PLATFROM_VERSION: base-type=uint8, compu {0=Cx00_INVALID, 1=Cx01_MRR3, 2=Cx02_SRR5, 3=Cx03_RACAM, 4=Cx04_MRR360, 5=Cx05_MRR3LLP, 6=Cx06_MRRLLP_STD, 7=Cx07_MRRLLP_AMOD, 8=Cx08_SRRAD, 9=Cx09_FLR4, 10=Cx0A_FLR4PLUS, 11=Cx0B_SRR6, 12=Cx0C_SRR6PLUS}, range raw 0..255
        STS_SMC_SECTION_COMPTBLITY: base-type=uint16, range phys 0..65535, raw 0..65535
        STS_USC_CAL_VER_MAJOR: base-type=uint16, range phys 0..65535, raw 0..65535
        STS_USC_CAL_VER_MINOR: base-type=uint16, range phys 0..65535, raw 0..65535
        STS_USC_SECTION_COMPTBLITY: base-type=uint16, range phys 0..255, raw 0..255
    SR_Status_Faults: category=STRUCTURE
      element STS_CORE_ACTIVE_FAULTS: category=VALUE, base-type=uint32, range phys 0..4294967295, raw 0..4294967295
    SR_Status_HW_CAN_Version: category=STRUCTURE
      9 x element, all with category=VALUE:
        STS_DET_DBC_BASE_VER_MAJOR: base-type=uint8, range phys 0..255, raw 0..255
        STS_DET_DBC_BASE_VER_MINOR: base-type=uint8, range phys 0..255, raw 0..255
        STS_HARDWARE_VERSION: base-type=uint8, range raw 0..255
        STS_PCAN_PROTOCOL_VER_MAJOR: base-type=uint8, range phys 0..255, raw 0..255
        STS_PCAN_PROTOCOL_VER_MINOR: base-type=uint8, range phys 0..255, raw 0..255
        STS_PLATFORM_VARIANT: base-type=uint8, compu {0=Cx00_VARIANT_INVALID, 1=Cx01_VARIANT_MRR3, 2=Cx02_VARIANT_SRR5, 3=Cx03_VARIANT_RACAM, 4=Cx04_VARIANT_MRR360, 5=Cx05_VARIANT_MRR3LLP, 6=Cx06_VARIANT_MRR3LLP_STD, 7=Cx07_VARIANT_MRR3LLP_AMOD, 8=Cx08_VARIANT_SRRAD, 9=Cx09_VARIANT_FLR4, 10=Cx0A_VARIANT_FLR4PLUS, 11=Cx0B_VARIANT_SRR6, 12=Cx0C_VARIANT_SRR6PLUS}, range raw 0..255
        STS_SERIAL_NUM_JULIAN_DAY: base-type=uint16, range phys 0..511, raw 0..511
        STS_SERIAL_NUM_JULIAN_YEAR: base-type=uint8, range phys 2020..2027, raw 0..7
        STS_SERIAL_NUMBER_SEQUENCE: base-type=uint16, range phys 0..4095, raw 0..4095
    SR_Status_MountingPos: category=STRUCTURE
      9 x element, all with category=VALUE:
        STS_SENSOR_HEIGHT: base-type=float32, range raw -3.4e+38..3.4e+38
        STS_SENSOR_MOUNT_LOCATION: base-type=uint8, range phys 0..15, raw 0..15
        STS_SENSOR_MOUNT_ORNT_PITCH: base-type=float32, range raw -3.4e+38..3.4e+38
        STS_SENSOR_MOUNT_ORNT_ROLL: base-type=float32, range raw -3.4e+38..3.4e+38
        STS_SENSOR_MOUNT_ORNT_YAW: base-type=float32, range raw -3.4e+38..3.4e+38
        STS_SENSOR_MOUNT_POS_X: base-type=float32, range raw -3.4e+38..3.4e+38
        STS_SENSOR_MOUNT_POS_Y: base-type=float32, range raw -3.4e+38..3.4e+38
        STS_SENSOR_MOUNT_POS_Z: base-type=float32, range raw -3.4e+38..3.4e+38
        STS_SENSOR_POSITION: base-type=uint8, range phys 0..15, raw 0..15
    SR_Status_Radar: category=STRUCTURE
      5 x element, all with category=VALUE:
        STS_AF_CORE_THROUGHPUT: base-type=float32, range raw 0..100
        STS_MMIC_RE_INIT_COUNT: base-type=uint8, range phys 0..15, raw 0..15
        STS_RDD_CORE_THROUGHPUT: base-type=float32, range raw 0..100
        STS_SCAN_TYPE: base-type=boolean, compu {0=Cx0_MEDIUM_LOOK, 1=Cx1_LONG_LOOK}, range raw 0..1
        STS_XCVR_OPERATIONAL: base-type=boolean, range phys 0..1, raw 0..1
    SR_Status_SensorPerformance: category=STRUCTURE
      element STS_BRR_STATUS: category=VALUE, base-type=uint8, compu {0=Cx0_INACTIVE, 1=Cx1_ACTIVE, 2=Cx2_FAULT}, range raw 0..2
    SR_Status_SwVersion: category=STRUCTURE
      8 x element, all with category=VALUE, base-type=uint8, range phys 0..255, raw 0..255:
        STS_PBL_VERSION_FIELD{1..4}
        STS_SW_VERSION_FIELD{1..4}
    SR_Status_Temperature: category=STRUCTURE
      5 x element, all with category=VALUE, base-type=sint16:
        STS_MCU_TEMP: range raw -50..205
        STS_MMIC_TEMP_RX: range raw -50..205
        STS_MMIC_TEMP_TX0: range raw -50..205
        STS_MMIC_TEMP_TX1_2: range phys -50..205, raw -50..205
        STS_MMIC_TEMP_TX3_4: range raw -50..205
    SR_Status_TimeSyncStatus: category=STRUCTURE
      element STS_NO_TSYN_ERROR: category=VALUE, base-type=boolean, range phys 0..1, raw 0..1
      element STS_POINT_OF_TRIGGER: category=VALUE, base-type=float32, range raw -3.4e+38..3.4e+38
      element STS_TIME_SYNC_OFFSET: category=VALUE, base-type=sint16, range phys -32768..32767, raw -32768..32767
    SR_Status_Vehicle: category=STRUCTURE
      6 x element, all with category=VALUE:
        STS_STEERING_ANGLE: base-type=float32, range raw -3.4e+38..3.4e+38
        STS_STEERING_ANGLE_SIGN: base-type=boolean, range phys 0..1, raw 0..1
        STS_VEH_SPEED_DIRECTION: base-type=boolean, range phys 0..1, raw 0..1
        STS_VEHICLE_SPEED_CALC: base-type=float32, range raw -3.4e+38..3.4e+38
        STS_VEHICLE_SUPPLY_VOLTAGE: base-type=uint8, compu {0=Cx0_normV, 1=Cx1_lowVtemp, 2=Cx2_lowVtempToNorm, 3=Cx3_lowV1, 4=Cx4_lowV2, 5=Cx5_lowV1ToNorm, 6=Cx6_lowV2ToNorm, 7=Cx7_highVtemp, 8=Cx8_highVtempToNorm, 9=Cx9_highV1, 10=CxA_highV2, 11=CxB_highV1ToNorm, 12=CxC_highV2ToNorm}, range raw 0..15
        STS_YAW_RATE_BIAS: base-type=float32, range raw -3.4e+38..3.4e+38
    SR_SystemStatusVehicle: category=STRUCTURE
      12 x element, all with category=VALUE:
        SSTS_STEERING_ANGLE: base-type=float32, range raw 0..3.141594
        SSTS_STEERING_ANGLE_SIGN: base-type=boolean, range phys 0..1, raw 0..1
        SSTS_VEH_ODOMETER: base-type=uint32, range phys 0..999999, raw 0..999999
        SSTS_VEH_POWER_MODE_STATUS: base-type=uint8, compu {0=Cx0_Off, 1=Cx1_Standby, 2=Cx2_Accessories, 3=Cx3_Ignition_On, 4=Cx4_HV_On, 5=Cx5_Reserved, 6=Cx6_Reserved, 7=Cx7_Invalid}, range raw 0..7
        SSTS_VEH_SPD_COMP_FACTOR: base-type=float32, range raw 0.75..1.248046875
        SSTS_VEH_SYSTEM_VOLTAGE: base-type=float32, range raw 0..255
        SSTS_VEHICLE_SPEED_CALC: base-type=float32, range raw 0..350
        SSTS_VEHICLE_SPEED_CALC_QF: base-type=uint8, compu {0=Cx0_Undefined, 1=Cx1_Temporarily_Undefined (Temporarily Undefined), 2=Cx2_Innaccurate, 3=Cx3_Accurate}, range raw 0..3
        SSTS_VEHICLE_STATE: base-type=uint8, compu {0=Cx0_Unknown, 1=Cx1_VehicleParked, 2=Cx2_VehicleAlive, 3=Cx3_VehicleEntry, 4=Cx4_VehicleDriving, 5=Cx5_VehicleUpgrade}, range raw 0..5
        SSTS_YAW_RATE_BIAS: base-type=float32, range raw 0..0.375
        SSTS_YAW_RATE_CALC: base-type=float32, range raw -2.24..2.24
        SSTS_YAW_RATE_CALC_QF: base-type=uint8, compu {0=Cx0_Undefined, 1=Cx1_Temporarily_Undefined (Temporarily Undefined), 2=Cx2_Innaccurate, 3=Cx3_Accurate}, range raw 0..3
    SR_SystemStatusVehicleState: category=STRUCTURE
      6 x element, all with category=VALUE:
        SSTS_DRIVE_DIR: base-type=uint8, range phys 0..3, raw 0..3
        SSTS_DRIVE_REVERSE: base-type=boolean, range phys 0..1, raw 0..1
        SSTS_GEAR_POSITION: base-type=uint8, compu {0=Cx0_Park, 1=Cx1_Reverse, 2=Cx2_Neutral, 3=Cx3_Drive, 4=Cx4_Sport_DriveSport, 5=Cx5_Low, 6=Cx6_first, 7=Cx7_second, 8=Cx8_third, 9=Cx9_fourth, 10=CxA_fifth, 11=CxB_sixth, 12=CxC_NotUsed_1, 13=CxD_NotUsed_2, 14=CxE_Unknown_Position, 15=CxF_Fault}, range raw 0..15
        SSTS_IGN_STATUS: base-type=uint8, compu {0=Cx0_Unknown, 1=Cx1_Off, 2=Cx2_Accessory, 4=Cx4_Run, 8=Cx8_Start, 15=CxF_Invalid}, range raw 0..15
        SSTS_LROS_DRIVE_DIR: base-type=uint8, compu {0=Cx0_Unknown, 1=Cx1_Backward, 2=Cx2_Forward, 4=Cx4_ (-)} "Source signal range: [0,3]", range raw 0..4
        SSTS_LROS_DRIVE_REVERSE: base-type=boolean, compu {0=Cx0_Not_Reverse, 1=Cx1_Reverse}, range raw 0..1
    SR_VEHICLE_STATUS_RECORD: category=STRUCTURE
      5 x element, all with category=TYPE_REFERENCE:
        System_Status_Vehicle: implementation-data-type=SR_SystemStatusVehicle
        System_Status_Vehicle_State: implementation-data-type=SR_SystemStatusVehicleState
        System_Status_ADAS_Version: implementation-data-type=System_Status_ADAS_Version
        System_Status_Absolute_Time: implementation-data-type=SR_SystemStatus_AbsoluteTime_impdt
        SSTS_EtoE_HDR: implementation-data-type=SR_EtoE_HDR
package /DataTypes/ImplementationDataTypes
  impl type System_Status_ADAS_Version: category=STRUCTURE
    element SSTS_CAN_PCAN_MINOR_ADAS: category=VALUE, base-type=uint8, range raw 0..255
    element SSTS_CAN_PCAN_MAJOR_ADAS: category=VALUE, base-type=uint8, range raw 0..255
    element SSTS_SW_VERSION_ADAS: category=VALUE, base-type=uint32, range raw 0..4294967295
package /DataTypes/Units
  7 x unit, all with factor-si-to-unit=1, offset-si-to-unit=0:
    MeterPerSecond: display-name=m/s
    Unit_Ratio: display-name=ratio
    U_dB: display-name=dB
    U_dBsm: display-name=dBsm
    U_m: display-name=m
    U_NA: display-name=NA
    U_rad: display-name=rad
